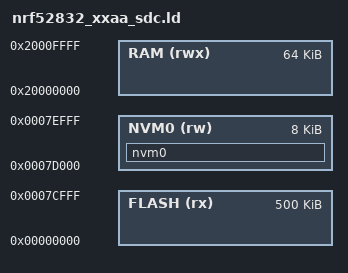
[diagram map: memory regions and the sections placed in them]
/* Linker script to configure memory regions. */

SEARCH_DIR(.)
SEARCH_DIR("../../../../ldscript")
SEARCH_DIR("../../../../../ldscript")
SEARCH_DIR("../../../../../../ldscript")
SEARCH_DIR("../../../../../../../ldscript")
SEARCH_DIR("../../IOsonata/ARM/ldscript")
SEARCH_DIR("../../../IOsonata/ARM/ldscript")
SEARCH_DIR("../../../../IOsonata/ARM/ldscript")
SEARCH_DIR("../../../../../IOsonata/ARM/ldscript")
SEARCH_DIR("../../../../../../IOsonata/ARM/ldscript")
GROUP(-lgcc -lc)

MEMORY
{
	/* App flash stops short of the store below, so an image that grows
	   into it fails to link rather than overlapping it. */
	FLASH (rx) : ORIGIN = 0x00000000, LENGTH = 0x7D000
	/* The bond store. Declared here so the linker owns the layout: FLASH
	   above stops short of it, so an image that grows into the store fails
	   to link. NvmRegionAddr(0) reads the section below, so nothing
	   states the address twice. */
	NVM0 (rw) : ORIGIN = 0x0007D000, LENGTH = 0x00002000
	RAM (rwx) : ORIGIN = 0x20000000, LENGTH = 0x10000
}

SECTIONS
{
	/* The region as a section, so the reservation shows up in the map file
	   with its size and the bounds arrive as __start_ and __stop_ symbols,
	   the naming the SDK uses for its own section variables. KEEP lets a
	   variable be placed in here later if anything ever wants to. */
	nvm0 (NOLOAD) :
	{
		__start_nvm0 = .;
		KEEP(*(nvm0))
		. = ORIGIN(NVM0) + LENGTH(NVM0);
		__stop_nvm0 = .;
	} > NVM0
}

SECTIONS
{
	. = ALIGN(4);
	.fs_data :
	{
		PROVIDE(__start_fs_data = .);
		KEEP(*(.fs_data))
		PROVIDE(__stop_fs_data = .);
	} > RAM AT > FLASH

	.log_dynamic_data :
	{
		PROVIDE(__start_log_dynamic_data = .);
		KEEP(*(.log_dynamic_data))
		PROVIDE(__stop_log_dynamic_data = .);
	} > RAM AT > FLASH
	
	.cli_sorted_cmd_ptrs :
	{
		PROVIDE(__start_cli_sorted_cmd_ptrs = .);
		KEEP(*(.cli_sorted_cmd_ptrs))
		PROVIDE(__stop_cli_sorted_cmd_ptrs = .);
	} > RAM AT > FLASH
} INSERT AFTER .data;

SECTIONS
{
	.pwr_mgmt_data :
	{
		PROVIDE(__start_pwr_mgmt_data = .);
		KEEP(*(SORT(.pwr_mgmt_data*)))
		PROVIDE(__stop_pwr_mgmt_data = .);
	} > FLASH
  
	.crypto_data :
	{
	    PROVIDE(__start_crypto_data = .);
	    KEEP(*(SORT(.crypto_data*)))
	    PROVIDE(__stop_crypto_data = .);
	} > FLASH

	.log_const_data :
	{
		PROVIDE(__start_log_const_data = .);
		KEEP(*(.log_const_data))
		PROVIDE(__stop_log_const_data = .);
	} > FLASH
  
	.cli_command :
	{
		PROVIDE(__start_cli_command = .);
		KEEP(*(.cli_command))
		PROVIDE(__stop_cli_command = .);
	} > FLASH
} INSERT AFTER .text

INCLUDE "gcc_arm_flash.ld"
